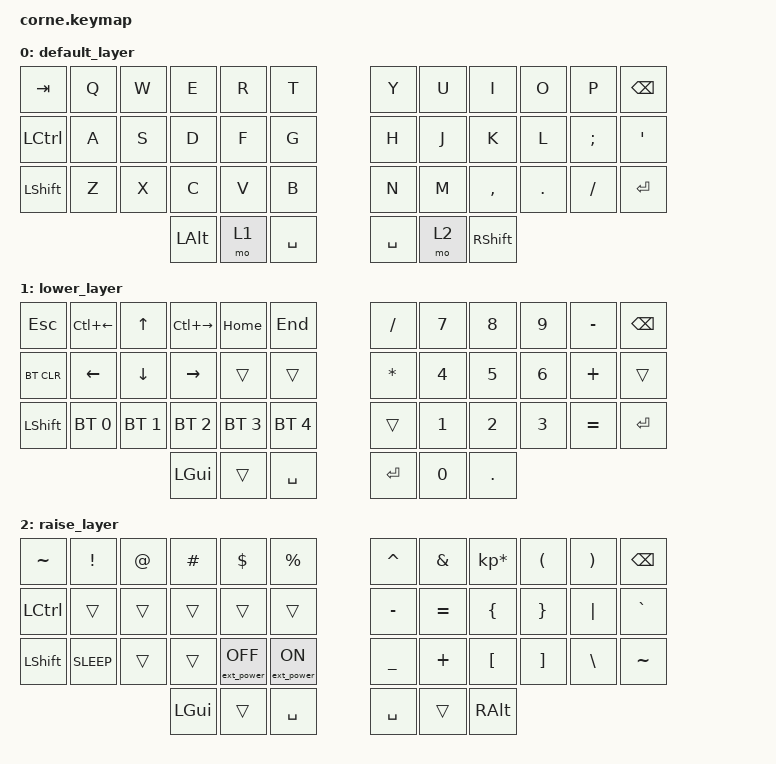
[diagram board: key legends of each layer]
/*
 * Copyright (c) 2020 The ZMK Contributors
 *
 * SPDX-License-Identifier: MIT
 */

#include <behaviors.dtsi>
#include <dt-bindings/zmk/keys.h>
#include <dt-bindings/zmk/bt.h>
#include <dt-bindings/zmk/ext_power.h>

/ {
        keymap {
                compatible = "zmk,keymap";

                default_layer {
// -----------------------------------------------------------------------------------------
// |  TAB |  Q  |  W  |  E  |  R  |  T  |   |  Y  |  U   |  I  |  O  |  P  | BKSP |
// | CTRL |  A  |  S  |  D  |  F  |  G  |   |  H  |  J   |  K  |  L  |  ;  |  '   |
// | SHFT |  Z  |  X  |  C  |  V  |  B  |   |  N  |  M   |  ,  |  .  |  /  | RET |
//                    | ALT | LWR | SPC |   | SPC | RSE  | SHFT |
                        bindings = <
   &kp TAB   &kp Q &kp W &kp E &kp R &kp T   &kp Y &kp U  &kp I     &kp O   &kp P    &kp BSPC
   &kp LCTRL &kp A &kp S &kp D &kp F &kp G   &kp H &kp J  &kp K     &kp L   &kp SEMI &kp SQT
   &kp LSHFT &kp Z &kp X &kp C &kp V &kp B   &kp N &kp M  &kp COMMA &kp DOT &kp FSLH &kp RET
                  &kp LALT &mo 1 &kp SPACE   &kp SPACE &mo 2 &kp RSHFT
                        >;
                };
                lower_layer {
// ----------------------------------------------------------------------------------------
// |  ESC |CT(L)|  UP |CT(R)| HOME| END |   |  /  |  7  |  8  |  9  |  -  | BKSP |
// | BTCLR| LFT | DWN | RGT | RGT | BT5 |   |  *  |  4  |  5  |  6  |  +  |      |
// | SHFT | BT1 | BT2 | BT3 | BT4 | BT5 |   |     |  1  |  2  |  3  |  =  | RET  |
//                    | GUI |     | SPC |   | SPC |  0  | .   |
                        bindings = <
   &kp ESC    &kp LC(LEFT) &kp UP       &kp LC(RIGHT)&kp HOME     &kp END           &kp FSLH &kp N7   &kp N8 &kp N9    &kp MINUS &kp BSPC
   &bt BT_CLR &kp LEFT     &kp DOWN     &kp RIGHT    &trans       &trans            &kp STAR &kp N4   &kp N5 &kp N6    &kp PLUS  &trans
   &kp LSHFT  &bt BT_SEL 0 &bt BT_SEL 1 &bt BT_SEL 2 &bt BT_SEL 3 &bt BT_SEL 4      &trans   &kp N1   &kp N2 &kp N3    &kp EQUAL &kp RET
                                        &kp LGUI     &trans       &kp SPACE         &kp RET  &kp N0   &kp DOT
                        >;
                };

                raise_layer {
// -----------------------------------------------------------------------------------------
// |  ~   |  !  |  @  |  #  |  $  |  %  |   |  ^  |  &  |  *  |  (  |  )  | BKSP |
// | CTRL |     |     |     |     |     |   |  -  |  =  |  {  |  }  | "|" |  `   |
// | SHFT | slp |     |     |pwrof|pwron|   |  _  |  +  |  [  |  ]  |  \  |  ~   | // TODO: Fix this row when &mkp is committed
//                    | GUI |     | SPC |   | SPC |     | ALT |
                        bindings = <
   &kp TILDE  &kp EXCL 	         &kp AT  &kp HASH  &kp DLLR 	     &kp PRCNT        	 &kp CARET &kp AMPS  &kp KP_MULTIPLY &kp LPAR &kp RPAR &kp BSPC
   &kp LCTRL  &trans   		 &trans  &trans    &trans    	     &trans           	 &kp MINUS &kp EQUAL &kp LBRC        &kp RBRC &kp PIPE &kp GRAVE
   &kp LSHFT  &kp K_SLEEP        &trans  &trans    &ext_power EP_OFF &ext_power EP_ON	 &kp UNDER &kp PLUS  &kp LBKT        &kp RBKT &kp BSLH &kp TILDE
                                   &kp LGUI &trans &kp SPACE  		      	 &kp SPACE &trans &kp RALT
                        >;
                };
        };
};
